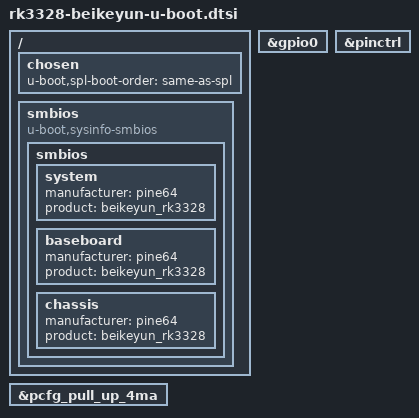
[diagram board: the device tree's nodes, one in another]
// SPDX-License-Identifier: GPL-2.0+
/*
 * (C) Copyright 2018-2019 Rockchip Electronics Co., Ltd
 */

#include "rk3328-u-boot.dtsi"
#include "rk3328-sdram-lpddr3-1600.dtsi"
/ {
	chosen {
		u-boot,spl-boot-order = "same-as-spl", &emmc, &sdmmc;
	};

	smbios {
		compatible = "u-boot,sysinfo-smbios";

		smbios {
			system {
				manufacturer = "pine64";
				product = "beikeyun_rk3328";
			};

			baseboard {
				manufacturer = "pine64";
				product = "beikeyun_rk3328";
			};

			chassis {
				manufacturer = "pine64";
				product = "beikeyun_rk3328";
			};
		};
	};
};

&gpio0 {
	u-boot,dm-spl;
};

&pinctrl {
	u-boot,dm-spl;
};

&pcfg_pull_up_4ma {
	u-boot,dm-spl;
};

